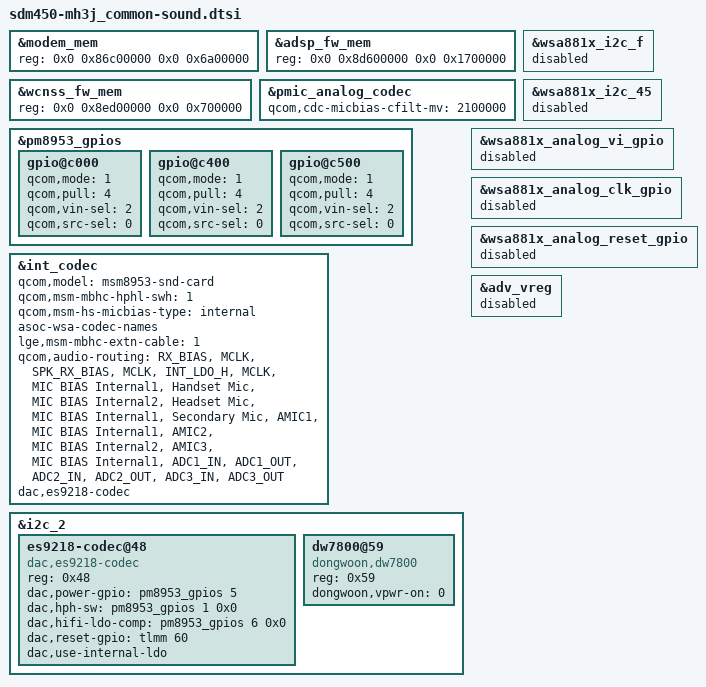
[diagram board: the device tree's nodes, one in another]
/*
 * Copyright (c) 2018, The Linux Foundation. All rights reserved.
 *
 * This program is free software; you can redistribute it and/or modify
 * it under the terms of the GNU General Public License version 2 and
 * only version 2 as published by the Free Software Foundation.
 *
 * This program is distributed in the hope that it will be useful,
 * but WITHOUT ANY WARRANTY; without even the implied warranty of
 * MERCHANTABILITY or FITNESS FOR A PARTICULAR PURPOSE.  See the
 * GNU General Public License for more details.
 */

#include "../../../qcom/msm8953-audio.dtsi"

&modem_mem {
	reg = <0x0 0x86c00000 0x0 0x6a00000>;
};

&adsp_fw_mem {
	reg = <0x0 0x8d600000 0x0 0x1700000>;
};

&wcnss_fw_mem {
	reg = <0x0 0x8ed00000 0x0 0x700000>;
};

&pmic_analog_codec {
    status = "okay";
    qcom,cdc-micbias-cfilt-mv = <2100000>;
};

&pm8953_gpios {
    gpio@c000 {
        qcom,mode = <1>;
        qcom,pull = <4>;
        qcom,vin-sel = <2>;
        qcom,src-sel = <0>;
        status = "okay";
    };
    gpio@c400 {
        qcom,mode = <1>;
        qcom,pull = <4>;
        qcom,vin-sel = <2>;
        qcom,src-sel = <0>;
        status = "okay";
    };
    gpio@c500 {
        qcom,mode = <1>;
        qcom,pull = <4>;
        qcom,vin-sel = <2>;
        qcom,src-sel = <0>;
        status = "okay";
    };
};

&int_codec {
    status = "okay";
    qcom,model = "msm8953-snd-card";
    qcom,msm-mbhc-hphl-swh = <1>;
    qcom,msm-hs-micbias-type = "internal";
    asoc-wsa-codec-names;
    lge,msm-mbhc-extn-cable = <1>;

    qcom,audio-routing =
        "RX_BIAS", "MCLK",
        "SPK_RX_BIAS", "MCLK",
        "INT_LDO_H", "MCLK",
        "MIC BIAS Internal1", "Handset Mic",
        "MIC BIAS Internal2", "Headset Mic",
        "MIC BIAS Internal1", "Secondary Mic",
        "AMIC1", "MIC BIAS Internal1",
        "AMIC2", "MIC BIAS Internal2",
        "AMIC3", "MIC BIAS Internal1",
        "ADC1_IN", "ADC1_OUT",
        "ADC2_IN", "ADC2_OUT",
        "ADC3_IN", "ADC3_OUT";
        dac,es9218-codec;
};

&i2c_2 {
    es9218-codec@48 {
        status = "okay";
        compatible = "dac,es9218-codec";
        reg = <0x48>;
        dac,power-gpio = <&pm8953_gpios 5 0x0>;
        dac,hph-sw = <&pm8953_gpios 1 0x0>;
        dac,hifi-ldo-comp = <&pm8953_gpios 6 0x0>;
        dac,reset-gpio = <&tlmm 60 0x0>;
        dac,use-internal-ldo;
    };
};

&wsa881x_i2c_f {
	status = "disabled";
};

&wsa881x_i2c_45 {
	status = "disabled";
};

&wsa881x_analog_vi_gpio {
	status = "disabled";
};

&wsa881x_analog_clk_gpio {
	status = "disabled";
};

&wsa881x_analog_reset_gpio {
	status = "disabled";
};

&adv_vreg {
    status = "disabled";
};

&i2c_2 {
	dw7800@59 {
		compatible = "dongwoon,dw7800";
		status = "ok";
		reg = <0x59>;
		dongwoon,vpwr-on = <0>;
	};
};
